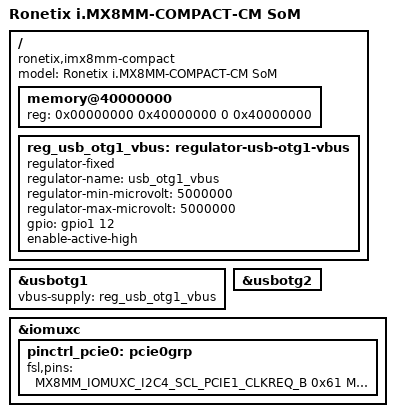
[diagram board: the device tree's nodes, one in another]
// SPDX-License-Identifier: (GPL-2.0+ OR MIT)
/*
 * Copyright 2021 Ronetix
 */

/dts-v1/;

#include <dt-bindings/phy/phy-imx8-pcie.h>
#include <dt-bindings/usb/pd.h>
#include "imx8mm.dtsi"
#include "imx8mm-ronetix.dtsi"

/ {
	model = "Ronetix i.MX8MM-COMPACT-CM SoM";
	compatible = "ronetix,imx8mm-compact", "fsl,imx8mm";

	/* 1 GiB @ 0x40000000 */
	memory@40000000 {
		device_type = "memory";
		reg = <0x00000000 0x40000000 0 0x40000000>;
	};

	reg_usb_otg1_vbus: regulator-usb-otg1-vbus {
		compatible = "regulator-fixed";
		regulator-name = "usb_otg1_vbus";
		regulator-min-microvolt = <5000000>;
		regulator-max-microvolt = <5000000>;
		gpio = <&gpio1 12 GPIO_ACTIVE_HIGH>;
		enable-active-high;
	};
};

&usbotg1 {
	vbus-supply = <&reg_usb_otg1_vbus>;
	status = "okay";
};

&usbotg2 {
	status = "okay";
};

&iomuxc {
	pinctrl_pcie0: pcie0grp {
		fsl,pins = <
			MX8MM_IOMUXC_I2C4_SCL_PCIE1_CLKREQ_B	0x61 /* PCIe_CLKREQ, open drain, pull up */
			MX8MM_IOMUXC_GPIO1_IO09_GPIO1_IO9	0x41 /* PCIe_nDIS */
			MX8MM_IOMUXC_SAI2_RXFS_GPIO4_IO21	0x41 /* PCIe_nRST */
		>;
	};
};
